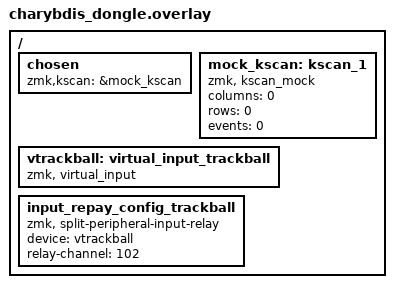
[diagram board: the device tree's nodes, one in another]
#include "charybdis.dtsi"

/ {
    chosen {
        zmk,kscan = &mock_kscan;
      };
      mock_kscan: kscan_1 {
          compatible = "zmk, kscan_mock";
          columns = <0>;
          rows = <0>;
          events = <0>;
        }
  };

/ {
    vtrackball: virtual_input_trackball {
        compatible = "zmk, virtual_input";
      };

      input_repay_config_trackball {
          compatible = "zmk, split-peripheral-input-relay";
          device = <&vtrackball>;
          relay-channel = <102>;
        };
  };
